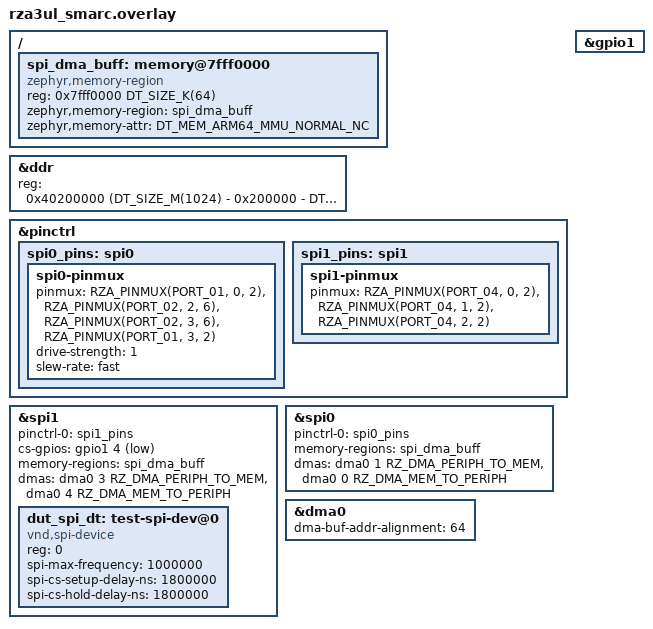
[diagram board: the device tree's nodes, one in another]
/*
 * Copyright (c) 2025 Renesas Electronics Corporation
 * SPDX-License-Identifier: Apache-2.0
 */

#include <zephyr/dt-bindings/memory-attr/memory-attr.h>
#include <zephyr/dt-bindings/memory-attr/memory-attr-arm64.h>

/*
 * Allocate a memory region for non-cacheable DMA buffer.
 * The region is carved off the top of the DDR the kernel uses.
 */
/ {
	spi_dma_buff: memory@7fff0000 {
		compatible = "zephyr,memory-region";
		reg = <0x7fff0000 DT_SIZE_K(64)>;
		#memory-region-cells = <0>;
		zephyr,memory-region = "spi_dma_buff";
		zephyr,memory-attr = <DT_MEM_ARM64_MMU_NORMAL_NC>;
	};
};

&ddr {
	reg = <0x40200000 (DT_SIZE_M(1024) - 0x200000 - DT_SIZE_K(64))>;
};

&pinctrl {
	/omit-if-no-ref/ spi0_pins: spi0 {
		spi0-pinmux {
			pinmux = <RZA_PINMUX(PORT_01, 0, 2)>, /* CK */
				 <RZA_PINMUX(PORT_02, 2, 6)>, /* MOSI */
				 <RZA_PINMUX(PORT_02, 3, 6)>, /* MISO */
				 <RZA_PINMUX(PORT_01, 3, 2)>; /* SSL */
			drive-strength = <1>;
			slew-rate = "fast";
		};
	};

	/omit-if-no-ref/ spi1_pins: spi1 {
		spi1-pinmux {
			pinmux = <RZA_PINMUX(PORT_04, 0, 2)>, /* CK */
				 <RZA_PINMUX(PORT_04, 1, 2)>, /* MOSI */
				 <RZA_PINMUX(PORT_04, 2, 2)>; /* MISO */
		};
	};
};

&gpio1 {
	status = "okay";
};

&spi1 {
	status = "okay";
	pinctrl-0 = <&spi1_pins>;
	pinctrl-names = "default";
	cs-gpios = <&gpio1 4 GPIO_ACTIVE_LOW>;
	memory-regions = <&spi_dma_buff>;

	dmas = <&dma0 3 RZ_DMA_PERIPH_TO_MEM>,
	       <&dma0 4 RZ_DMA_MEM_TO_PERIPH>;
	dma-names = "rx", "tx";

	dut_spi_dt: test-spi-dev@0 {
		compatible = "vnd,spi-device";
		reg = <0>;
		spi-max-frequency = <1000000>;
		spi-cs-setup-delay-ns = <1800000>;
		spi-cs-hold-delay-ns = <1800000>;
	};
};

dut_spis: &spi0 {
	status = "okay";
	pinctrl-0 = <&spi0_pins>;
	pinctrl-names = "default";
	memory-regions = <&spi_dma_buff>;

	dmas = <&dma0 1 RZ_DMA_PERIPH_TO_MEM>,
	       <&dma0 0 RZ_DMA_MEM_TO_PERIPH>;
	dma-names = "rx", "tx";
};

&dma0 {
	status = "okay";
	dma-buf-addr-alignment = <64>;
};
